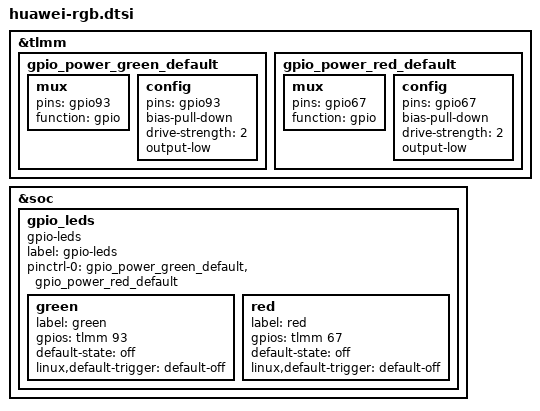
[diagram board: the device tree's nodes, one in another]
&tlmm {
	gpio_power_green_default: gpio_power_green_default {
		/* front and wide DVDD */
		mux {
			pins = "gpio93";
			function = "gpio";
		};

		config {
			pins = "gpio93";
			bias-pull-down; /* PULL DOWN */
			drive-strength = <2>; /* 2 MA */
			output-low;
		};
	};

	gpio_power_red_default: gpio_power_red_default {
		/* front and wide DVDD */
		mux {
			pins = "gpio67";
			function = "gpio";
		};

		config {
			pins = "gpio67";
			bias-pull-down; /* PULL DOWN */
			drive-strength = <2>; /* 2 MA */
			output-low;
		};
	};
};

&soc {
	gpio_leds {
		compatible = "gpio-leds";
		label = "gpio-leds";

		pinctrl-names = "default";
		pinctrl-0 = <&gpio_power_green_default
			     &gpio_power_red_default>;

		green {
			label = "green";
			gpios = <&tlmm 93 GPIO_ACTIVE_HIGH>;
                        default-state = "off";
                        linux,default-trigger = "default-off";
		};

		red {
			label = "red";
			gpios = <&tlmm 67 GPIO_ACTIVE_HIGH>;
                        default-state = "off";
                        linux,default-trigger = "default-off";
		};

	};

};

